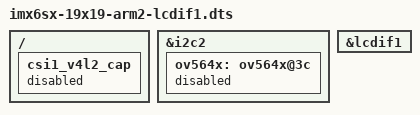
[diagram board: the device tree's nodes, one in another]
/*
 * Copyright (C) 2014 Freescale Semiconductor, Inc.
 *
 * This program is free software; you can redistribute it and/or modify
 * it under the terms of the GNU General Public License version 2 as
 * published by the Free Software Foundation.
 */

#include "imx6sx-19x19-arm2.dts"

/ {
	csi1_v4l2_cap {
		status = "disabled";
	};
};

&i2c2 {
	ov564x: ov564x@3c {
		status = "disabled";
	};
};

&lcdif1 {
	status = "okay";
};
